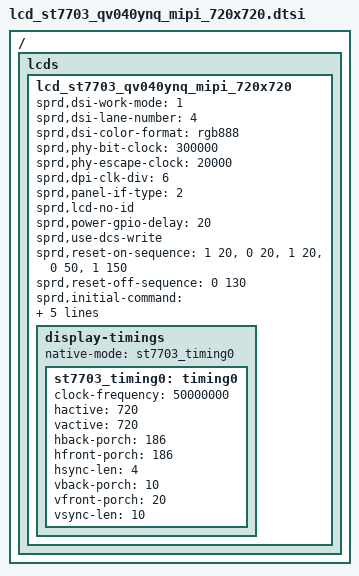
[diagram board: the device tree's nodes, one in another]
/*
 * Anbernic RG Cube -- ST7703 720x720 square MIPI-DSI panel.
 *
 * Transcribed mechanically from the stock DTB (docs/dts/cube/board.dts), which
 * was decompiled from the shipped Android dtbo. Every value below is the
 * vendor's; nothing here is derived or guessed.
 *
 * Cross-checked against the stock LK boot log (uboot_log partition):
 *   [mipi_dphy_configure] lanes : 4 / freq : 300000    -> lane count, bit clock
 *   [dispc_clk_init] DPI_CLK_SRC = 256000000, DPI_CLK_DIV = 6  -> dpi-clk-div
 *   lcd_name=lcd_st7703_qv040ynq_mipi_720x720 lcd_size=720x720
 *
 * Panel power/reset GPIOs are deliberately NOT here: sprd_panel.c reads those
 * from the board's lcd-panel node, not from this one. The Cube uses avdd
 * GPIO 86 and reset GPIO 11 and has NO avee rail -- the ums9620_2h10 reference
 * board's 192/191/11 must not be copied.
 */

/ { lcds {
	lcd_st7703_qv040ynq_mipi_720x720: lcd_st7703_qv040ynq_mipi_720x720 {

		sprd,dsi-work-mode = <1>;	/* video burst mode */
		sprd,dsi-lane-number = <4>;
		sprd,dsi-color-format = "rgb888";

		sprd,phy-bit-clock = <300000>;	/* kbps */
		sprd,phy-escape-clock = <20000>;	/* kHz */
		sprd,dpi-clk-div = <6>;
		sprd,panel-if-type = <2>;

		/*
		 * This panel returns no usable ID. The stock LK log shows
		 *   [st7703_readid] st7703_readid 98, read_buf[0]:0x0
		 *   [st7703_readid] config lcd i2c bias power failed
		 *   [st7703_readid] st7703_qv040ynq_driver read id success!
		 * i.e. the read yields 0x0 and the vendor reports success anyway.
		 * Skip ID matching rather than encode a value the panel never returns.
		 * (The same log line is why there is no sprd,power-i2c-* group here:
		 * the bias-power I2C configure fails on this board and is not used.)
		 */
		sprd,lcd-no-id;

		sprd,power-gpio-delay = <20>;
		sprd,use-dcs-write;

		/* <level delay-ms> pairs */
		sprd,reset-on-sequence = <1 20>, <0 20>, <1 20>, <0 50>, <1 150>;
		sprd,reset-off-sequence = <0 130>;

		/* each command: <type> <delay-hi> <delay-lo> <len> <cmd> [payload] */
		sprd,initial-command = [
			39 00 00 04 b9 f1 12 83
			39 00 00 06 b1 00 00 00 da 80
			39 00 00 04 b2 3c 12 30
			39 00 00 0b b3 10 10 28 28 03 ff 00 00 00 00
			23 00 00 02 b4 80
			39 00 00 03 b5 0a 0a
			39 00 00 03 b6 7c 7c
			39 00 00 05 b8 26 22 f0 13
			39 00 00 1c ba 33 81 05 f9 0e 0e 20 00 00 00 00 00 00 00 44
				25 00 90 0a 00 00 01 4f 01 00 00 37
			23 00 00 02 bc 47
			39 00 00 04 bf 02 11 00
			39 00 00 0a c0 73 73 50 50 00 00 12 70 00
			39 00 00 0d c1 25 00 32 32 77 e4 ff ff cc cc 77 77
			39 00 00 07 c6 82 00 bf ff 00 ff
			39 00 00 07 c7 b8 00 0a 00 00 00
			39 00 00 05 c8 10 40 1e 02
			23 00 00 02 cc 0b
			39 00 00 23 e0 00 0b 10 2c 3d 3f 42 3a 07 0d 0f 13 15 13 14
				0f 16 00 0b 10 2c 3d 3f 42 3a 07 0d 0f 13 15 13
				14 0f 16
			39 00 00 0f e3 07 07 0b 0b 0b 0b 00 00 00 00 ff 00 c0 10
			39 00 00 40 e9 c8 10 0a 00 00 80 81 12 31 23 4f 86 a0 00 47
				08 00 00 0c 00 00 00 00 00 0c 00 00 00 98 02 8b
				af 46 02 88 88 88 88 88 98 13 8b af 57 13 88 88
				88 88 88 00 00 00 00 00 00 00 00 00 00 00 00 00
			39 00 00 3e ea 97 0c 09 09 09 78 00 00 00 00 00 00 9f 31 8b
				a8 31 75 88 88 88 88 88 9f 20 8b a8 20 64 88 88
				88 88 88 23 00 00 02 71 00 00 00 00 00 00 00 00
				00 00 00 00 00 00 00 40 80 81 00 00 00 00
			39 00 00 04 ef ff ff 01
			05 fa 00 01 11
			05 78 00 01 29
			];

		sprd,sleep-in-command = [
			13 78 00 01 28
			13 78 00 01 10
			];

		sprd,sleep-out-command = [
			13 fa 00 01 11
			13 78 00 01 29
			];

		display-timings {
			native-mode = <&st7703_timing0>;

			st7703_timing0: timing0 {
				clock-frequency = <50000000>;
				hactive = <720>;
				vactive = <720>;
				hback-porch = <186>;
				hfront-porch = <186>;
				hsync-len = <4>;
				vback-porch = <10>;
				vfront-porch = <20>;
				vsync-len = <10>;
			};
		};
	};
}; };
